VERSION ""

NS_ :

BS_:

BU_:

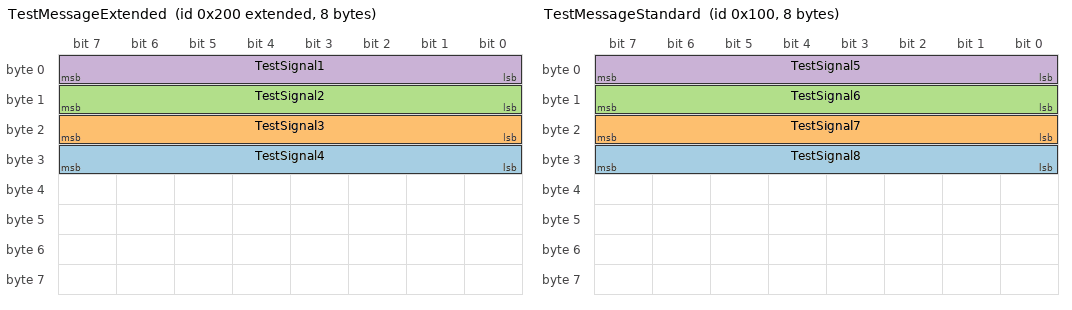
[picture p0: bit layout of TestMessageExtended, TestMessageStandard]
BO_ 2147484160 TestMessageExtended: 8 Vector__XXX
 SG_ TestSignal4 : 24|8@1- (1,0) [0|0] "" Vector__XXX
 SG_ TestSignal3 : 16|8@1- (1,0) [0|0] "" Vector__XXX
 SG_ TestSignal2 : 8|8@1- (1,0) [0|0] "" Vector__XXX
 SG_ TestSignal1 : 0|8@1- (1,0) [0|0] "" Vector__XXX

BO_ 256 TestMessageStandard: 8 Vector__XXX
 SG_ TestSignal8 : 24|8@1- (1,0) [0|0] "" Vector__XXX
 SG_ TestSignal7 : 16|8@1- (1,0) [0|0] "" Vector__XXX
 SG_ TestSignal6 : 8|8@1- (1,0) [0|0] "" Vector__XXX
 SG_ TestSignal5 : 0|8@1- (1,0) [0|0] "" Vector__XXX

BA_DEF_ SG_  "GenSigSendType" ENUM  "Cyclic","OnWrite","OnWriteWithRepetition","OnChange","OnChangeWithRepetition","IfActive","IfActiveWithRepetition","NoSigSendType";
BA_DEF_ BO_  "GenMsgSendType" ENUM  "Cyclic","not_used","not_used","not_used","not_used","Cyclic","not_used","IfActive","NoMsgSendType";
BA_DEF_  "DBName" STRING ;
BA_DEF_  "BusType" STRING ;
BA_DEF_DEF_  "GenSigSendType" "Cyclic";
BA_DEF_DEF_  "GenMsgSendType" "NoMsgSendType";
BA_DEF_DEF_  "DBName" "";
BA_DEF_DEF_  "BusType" "CAN";
BA_ "DBName" "SimpleDBC";
